# G32R501 register map
Vendor: Geehy Semiconductor Co., Ltd.; Series: G32R5; File version: 1.0
CPU: CM55 r0p1, little endian, MPU, FPU, double-precision FPU, DSP, VTOR, 4 interrupt priority bits
Registers are 32-bit, read-write, reset 0x0 unless marked. A register's access mark holds for its fields unless they carry their own. Offsets are from the block's base; [hi:lo] are bit positions.

## FSI_RX — Fast Serial Interface
Base 0x50101000
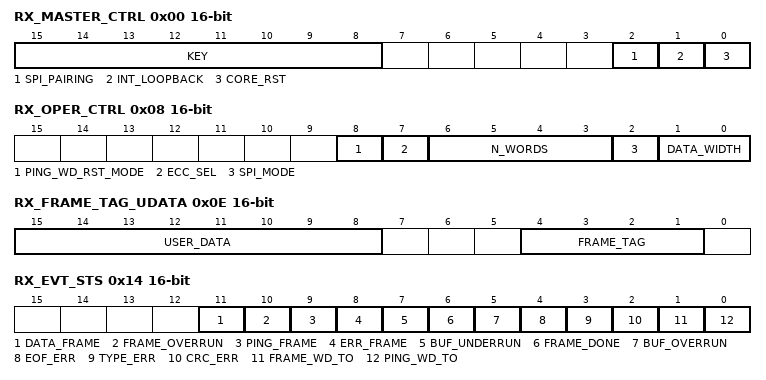
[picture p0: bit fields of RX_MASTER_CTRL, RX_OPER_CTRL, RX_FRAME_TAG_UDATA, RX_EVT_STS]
0x00 RX_MASTER_CTRL 16-bit access per field — Receive master control register
  [15:8] KEY wo — Write Key
  [2] SPI_PAIRING rw — Clock Pairing for SPI-like Behavior Enable bit
  [1] INT_LOOPBACK rw — Internal Loopback Enable bit
  [0] CORE_RST rw — Receiver Main Core Reset bit
0x08 RX_OPER_CTRL 16-bit — Receive operation control register
  [8] PING_WD_RST_MODE — Ping Watchdog Timeout Mode Select bit
  [7] ECC_SEL — ECC Data Width Select bit
  [6:3] N_WORDS — Number of Words to Receive
  [2] SPI_MODE — SPI Mode Enable bit
  [1:0] DATA_WIDTH — Receive Data Width Select bit
0x0C RX_FRAME_INFO 16-bit ro — Receive frame control register
  [3:0] FRAME_TYPE — Received Frame Type
0x0E RX_FRAME_TAG_UDATA 16-bit ro — Receive frame tag and user data register
  [15:8] USER_DATA — Received User Data
  [4:1] FRAME_TAG — Received Frame Tag
0x10 RX_DMA_CTRL 16-bit — Receive DMA event control register
  [0] DMA_EVT_EN — DMA Event Enable bit
0x14 RX_EVT_STS 16-bit ro — Receive event and error status flag register
  [11] DATA_FRAME — Data Frame Received Flag
  [10] FRAME_OVERRUN — Frame Overrun Flag
  [9] PING_FRAME — Ping Frame Received Flag
  [8] ERR_FRAME — Error Frame Received Flag
  [7] BUF_UNDERRUN — Receive Buffer Underrun Flag
  [6] FRAME_DONE — Frame Done Flag
  [5] BUF_OVERRUN — Receive Buffer Overrun Flag
  [4] EOF_ERR — End-of-Frame Error Flag
  [3] TYPE_ERR — Frame Type Error Flag
  [2] CRC_ERR — CRC Error Flag
  [1] FRAME_WD_TO — Frame Watchdog Timeout Flag
  [0] PING_WD_TO — Ping Watchdog Timeout Flag
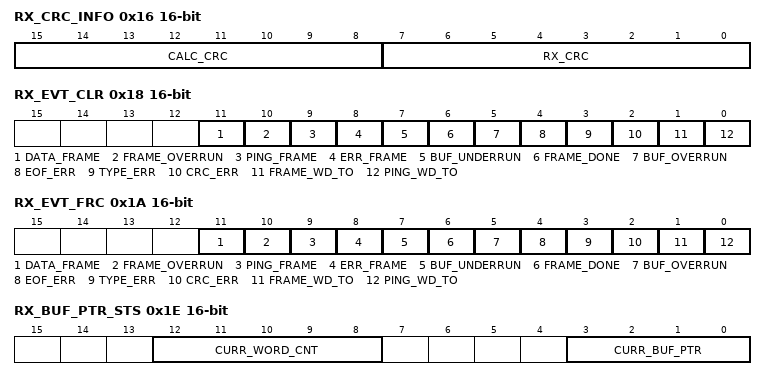
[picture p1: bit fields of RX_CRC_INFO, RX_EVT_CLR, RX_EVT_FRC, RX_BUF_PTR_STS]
0x16 RX_CRC_INFO 16-bit ro — Receive CRC info of received and computed CRC
  [15:8] CALC_CRC — Harware Calculated CRC Value
  [7:0] RX_CRC — Received CRC Value
0x18 RX_EVT_CLR 16-bit wo — Receive event and error clear register
  [11] DATA_FRAME — Data Frame Received Flag Clear bit
  [10] FRAME_OVERRUN — Frame Overrun Flag Clear bit
  [9] PING_FRAME — Ping Frame Received Flag Clear bit
  [8] ERR_FRAME — Error Frame Received Flag Clear bit
  [7] BUF_UNDERRUN — Receive Buffer Underrun Flag Clear bit
  [6] FRAME_DONE — Frame Done Flag Clear bit
  [5] BUF_OVERRUN — Receive Buffer Overrun Flag Clear bit
  [4] EOF_ERR — End-of-Frame Error Flag Clear bit
  [3] TYPE_ERR — Frame Type Error Flag Clear bit
  [2] CRC_ERR — CRC Error Flag Clear bit
  [1] FRAME_WD_TO — Frame Watchdog Timeout Flag Clear bit
  [0] PING_WD_TO — Ping Watchdog Timeout Flag Clear bit
0x1A RX_EVT_FRC 16-bit wo — Receive event and error flag force register
  [11] DATA_FRAME — Data Frame Received Flag Force bit
  [10] FRAME_OVERRUN — Frame Overrun Flag Force bit
  [9] PING_FRAME — Ping Frame Received Flag Force bit
  [8] ERR_FRAME — Error Frame Received Flag Force bit
  [7] BUF_UNDERRUN — Receive Buffer Underrun Flag Force bit
  [6] FRAME_DONE — Frame Done Flag Force bit
  [5] BUF_OVERRUN — Receive Buffer Overrun Flag Force bit
  [4] EOF_ERR — End-of-Frame Error Flag Force bit
  [3] TYPE_ERR — Frame Type Error Flag Force bit
  [2] CRC_ERR — CRC Error Flag Force bit
  [1] FRAME_WD_TO — Frame Watchdog Timeout Flag Force bit
  [0] PING_WD_TO — Ping Watchdog Timeout Flag Force bit
0x1C RX_BUF_PTR_LOAD 16-bit — Receive buffer pointer load register
  [3:0] BUF_PTR_LOAD — Buffer Pointer Load.
0x1E RX_BUF_PTR_STS 16-bit ro — Receive buffer pointer status register
  [12:8] CURR_WORD_CNT — Words Available in the Receive Buffer
  [3:0] CURR_BUF_PTR — Current Buffer Pointer Index
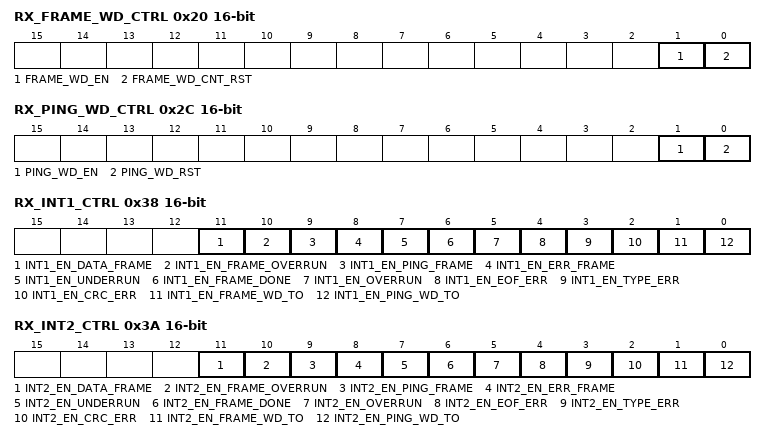
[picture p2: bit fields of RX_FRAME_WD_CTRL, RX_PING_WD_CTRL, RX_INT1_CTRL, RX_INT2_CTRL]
0x20 RX_FRAME_WD_CTRL 16-bit — Receive frame watchdog control register
  [1] FRAME_WD_EN — Frame Watchdog Counter Enable bit
  [0] FRAME_WD_CNT_RST — Frame Watchdog Counter Reset bit
0x24 RX_FRAME_WD_REF — Receive frame watchdog counter reference
  [31:0] FRAME_WD_REF — Frame Watchdog Counter Reference Value
0x28 RX_FRAME_WD_CNT ro — Receive frame watchdog current count
  [31:0] FRAME_WD_CNT — Frame Watchdog Counter Value
0x2C RX_PING_WD_CTRL 16-bit — Receive ping watchdog control register
  [1] PING_WD_EN — Ping Watchdog Counter Enable bit
  [0] PING_WD_RST — Ping Watchdog Counter Reset bit
0x2E RX_PING_TAG 16-bit ro — Receive ping tag register
  [4:1] PING_TAG — Received Ping Frame Tag
0x30 RX_PING_WD_REF — Receive ping watchdog counter reference
  [31:0] PING_WD_REF — Ping Watchdog Counter Reference Value
0x34 RX_PING_WD_CNT ro — Receive pingwatchdog current count
  [31:0] PING_WD_CNT — Ping Watchdog Counter Value
0x38 RX_INT1_CTRL 16-bit — Receive interrupt control register
  [11] INT1_EN_DATA_FRAME — Enable Data Frame Received Interrupt to INT1 bit
  [10] INT1_EN_FRAME_OVERRUN — Enable Frame Overrun Interrupt to INT1 bit
  [9] INT1_EN_PING_FRAME — Enable Ping Frame Received Interrupt to INT1 bit
  [8] INT1_EN_ERR_FRAME — Enable ERROR Frame Received Interrupt to INT1 bit
  [7] INT1_EN_UNDERRUN — Enable Buffer Underrun Interrupt to INT1 bit
  [6] INT1_EN_FRAME_DONE — Enable Frame Done Interrupt to INT1 bit
  [5] INT1_EN_OVERRUN — Enable Receive Buffer Overrun Interrupt to INT1 bit
  [4] INT1_EN_EOF_ERR — Enable End-of-Frame Error Interrupt to INT1 bit
  [3] INT1_EN_TYPE_ERR — Enable Frame Type Error Interrupt to INT1 bit
  [2] INT1_EN_CRC_ERR — Enable CRC Error Interrupt to INT1 bit
  [1] INT1_EN_FRAME_WD_TO — Enable Frame Watchdog Timeout Interrupt to INT1 bit
  [0] INT1_EN_PING_WD_TO — Enable Ping Watchdog Timeout Interrupt to INT1 bit
0x3A RX_INT2_CTRL 16-bit — Receive interrupt control register
  [11] INT2_EN_DATA_FRAME — Enable Data Frame Received Interrupt to INT2 bit
  [10] INT2_EN_FRAME_OVERRUN — Enable Frame Overrun Interrupt to INT2 bit
  [9] INT2_EN_PING_FRAME — Enable Ping Frame Received Interrupt to INT2 bit
  [8] INT2_EN_ERR_FRAME — Enable ERROR Frame Received Interrupt to INT2 bit
  [7] INT2_EN_UNDERRUN — Enable Buffer Underrun Interrupt to INT2 bit
  [6] INT2_EN_FRAME_DONE — Enable Frame Done Interrupt to INT2 bit
  [5] INT2_EN_OVERRUN — Enable Receive Buffer Overrun Interrupt to INT2 bit
  [4] INT2_EN_EOF_ERR — Enable End-of-Frame Error Interrupt to INT2 bit
  [3] INT2_EN_TYPE_ERR — Enable Frame Type Error Interrupt to INT2 bit
  [2] INT2_EN_CRC_ERR — Enable CRC Error Interrupt to INT2 bit
  [1] INT2_EN_FRAME_WD_TO — Enable Frame Watchdog Timeout Interrupt to INT2 bit
  [0] INT2_EN_PING_WD_TO — Enable Ping Watchdog Timeout Interrupt to INT2 bit
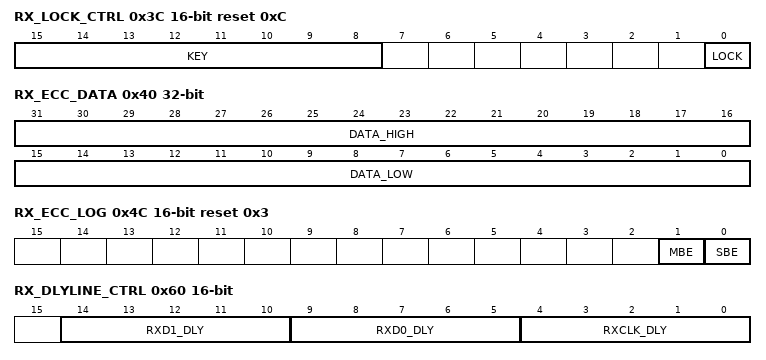
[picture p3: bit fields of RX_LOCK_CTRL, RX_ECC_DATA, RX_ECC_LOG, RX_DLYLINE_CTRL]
0x3C RX_LOCK_CTRL 16-bit access per field reset 0xC — Receive lock control register
  [15:8] KEY wo — Write Key
  [0] LOCK rw — Control Register Lock Enable bit
0x40 RX_ECC_DATA — Receive ECC data register
  [31:16] DATA_HIGH — Upper 16 bits of ECC Data
  [15:0] DATA_LOW — Lower 16 bits of ECC Data
0x44 RX_ECC_VAL — Receive ECC value register
  [6:0] ECC_VAL — ECC Value for SEC-DED check
0x48 RX_ECC_SEC_DATA ro — Receive ECC corrected data register
  [31:0] SEC_DATA — ECC Single Error Corrected Data
0x4C RX_ECC_LOG 16-bit ro reset 0x3 — Receive ECC log and status register
  [1] MBE — Multiple Bit Errors Detected
  [0] SBE — Single Bit Error Detected
0x60 RX_DLYLINE_CTRL 16-bit — Receive delay line control register
  [14:10] RXD1_DLY — Delay Line Tap Select for RXD1
  [9:5] RXD0_DLY — Delay Line Tap Select for RXD0
  [4:0] RXCLK_DLY — Delay Line Tap Select for RXCLK
0x70 RX_VIS_1 ro — Receive debug visibility register
  [3] RX_CORE_STS — Receiver Core Status bit
0x80 RX_BUF_BASE 16-bit ro — Base address for receive data buffer
  [15:0] BASE_ADDRESS — Receive Data Buffer Base Address
